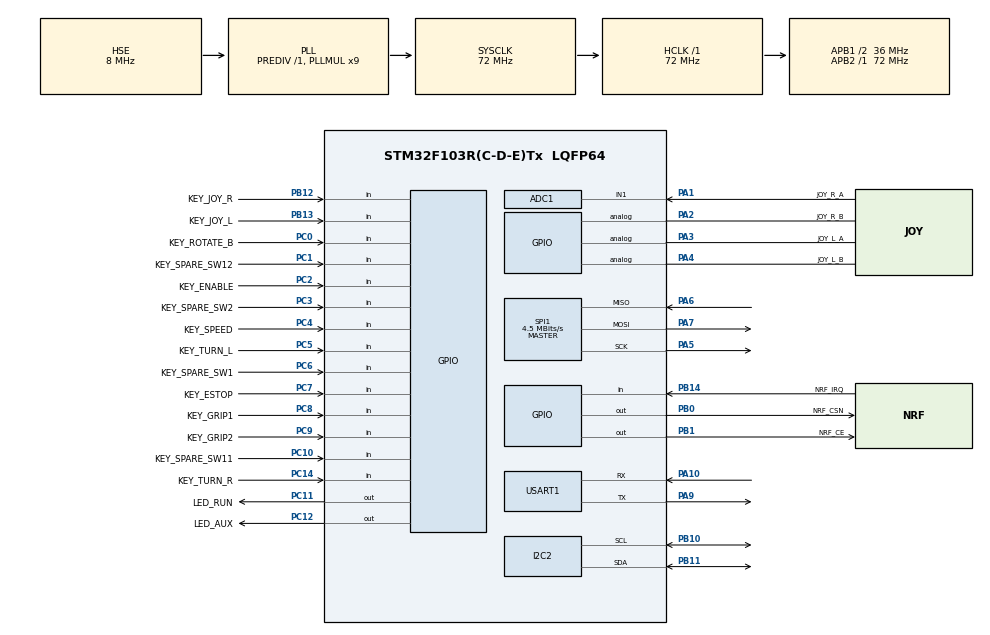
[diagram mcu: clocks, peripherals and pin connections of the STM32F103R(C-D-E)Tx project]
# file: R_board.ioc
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ADC1.Channel-0\#ChannelRegularConversion=ADC_CHANNEL_1
ADC1.NbrOfConversionFlag=1
ADC1.Rank-0\#ChannelRegularConversion=1
ADC1.SamplingTime-0\#ChannelRegularConversion=ADC_SAMPLETIME_239CYCLES_5
ADC1.master=1
I2C2.NoStretchMode=I2C_NOSTRETCH_ENABLE
Mcu.Family=STM32F1
Mcu.Name=STM32F103R(C-D-E)Tx
Mcu.Package=LQFP64
NVIC.PriorityGroup=NVIC_PRIORITYGROUP_4
PA1.GPIO_Label=JOY_R_A
PA1.Signal=ADCx_IN1
PA10.Mode=Asynchronous
PA10.Signal=USART1_RX
PA13.Mode=Serial_Wire
PA13.Signal=SYS_JTMS-SWDIO
PA14.Mode=Serial_Wire
PA14.Signal=SYS_JTCK-SWCLK
PA2.GPIO_Label=JOY_R_B
PA2.Signal=GPIO_Analog
PA3.GPIO_Label=JOY_L_A
PA3.Signal=GPIO_Analog
PA4.GPIO_Label=JOY_L_B
PA4.Signal=GPIO_Analog
PA5.Mode=Full_Duplex_Master
PA5.Signal=SPI1_SCK
PA6.Mode=Full_Duplex_Master
PA6.Signal=SPI1_MISO
PA7.Mode=Full_Duplex_Master
PA7.Signal=SPI1_MOSI
PA9.Mode=Asynchronous
PA9.Signal=USART1_TX
PB0.GPIO_Label=NRF_CSN
PB0.GPIO_PuPd=GPIO_NOPULL
PB0.PinState=GPIO_PIN_SET
PB0.Signal=GPIO_Output
PB1.GPIO_Label=NRF_CE
PB1.Signal=GPIO_Output
PB10.Mode=I2C
PB10.Signal=I2C2_SCL
PB11.Mode=I2C
PB11.Signal=I2C2_SDA
PB12.GPIO_Label=KEY_JOY_R
PB12.GPIO_PuPd=GPIO_PULLUP
PB12.Signal=GPIO_Input
PB13.GPIO_Label=KEY_JOY_L
PB13.GPIO_PuPd=GPIO_PULLUP
PB13.Signal=GPIO_Input
PB14.GPIO_Label=NRF_IRQ
PB14.Signal=GPIO_Input
PC0.GPIO_Label=KEY_ROTATE_B
PC0.GPIO_PuPd=GPIO_PULLUP
PC0.Signal=GPIO_Input
PC1.GPIO_Label=KEY_SPARE_SW12
PC1.GPIO_PuPd=GPIO_PULLUP
PC1.Signal=GPIO_Input
PC10.GPIO_Label=KEY_SPARE_SW11
PC10.GPIO_PuPd=GPIO_PULLUP
PC10.Signal=GPIO_Input
PC11.GPIO_Label=LED_RUN
PC11.GPIO_Speed=GPIO_SPEED_FREQ_HIGH
PC11.Signal=GPIO_Output
PC12.GPIO_Label=LED_AUX
PC12.PinState=GPIO_PIN_SET
PC12.Signal=GPIO_Output
PC14-OSC32_IN.GPIO_Label=KEY_TURN_R
PC14-OSC32_IN.GPIO_PuPd=GPIO_PULLUP
PC14-OSC32_IN.Signal=GPIO_Input
PC2.GPIO_Label=KEY_ENABLE
PC2.GPIO_PuPd=GPIO_PULLUP
PC2.Signal=GPIO_Input
PC3.GPIO_Label=KEY_SPARE_SW2
PC3.GPIO_PuPd=GPIO_PULLUP
PC3.Signal=GPIO_Input
PC4.GPIO_Label=KEY_SPEED
PC4.GPIO_PuPd=GPIO_PULLUP
PC4.Signal=GPIO_Input
PC5.GPIO_Label=KEY_TURN_L
PC5.GPIO_PuPd=GPIO_PULLUP
PC5.Signal=GPIO_Input
PC6.GPIO_Label=KEY_SPARE_SW1
PC6.GPIO_PuPd=GPIO_PULLUP
PC6.Signal=GPIO_Input
PC7.GPIO_Label=KEY_ESTOP
PC7.GPIO_PuPd=GPIO_PULLUP
PC7.Signal=GPIO_Input
PC8.GPIO_Label=KEY_GRIP1
PC8.GPIO_PuPd=GPIO_PULLUP
PC8.Signal=GPIO_Input
PC9.GPIO_Label=KEY_GRIP2
PC9.GPIO_PuPd=GPIO_PULLUP
PC9.Signal=GPIO_Input
PD0-OSC_IN.Mode=HSE-External-Oscillator
PD0-OSC_IN.Signal=RCC_OSC_IN
PD1-OSC_OUT.Mode=HSE-External-Oscillator
PD1-OSC_OUT.Signal=RCC_OSC_OUT
ProjectManager.HeapSize=0x200
ProjectManager.StackSize=0x400
ProjectManager.TargetToolchain=CMake
RCC.ADCPresc=RCC_ADCPCLK2_DIV6
RCC.AHBFreq_Value=72000000
RCC.APB1CLKDivider=RCC_HCLK_DIV2
RCC.APB1Freq_Value=36000000
RCC.APB1TimFreq_Value=72000000
RCC.APB2Freq_Value=72000000
RCC.APB2TimFreq_Value=72000000
RCC.HCLKFreq_Value=72000000
RCC.PLLMUL=RCC_PLL_MUL9
RCC.PLLSourceVirtual=RCC_PLLSOURCE_HSE
RCC.SYSCLKFreq_VALUE=72000000
RCC.SYSCLKSource=RCC_SYSCLKSOURCE_PLLCLK
RCC.USBFreq_Value=72000000
SH.ADCx_IN1.0=ADC1_IN1,IN1
SPI1.BaudRatePrescaler=SPI_BAUDRATEPRESCALER_16
SPI1.CalculateBaudRate=4.5 MBits/s
SPI1.Direction=SPI_DIRECTION_2LINES
SPI1.Mode=SPI_MODE_MASTER
SPI1.VirtualType=VM_MASTER
TIM2.Prescaler=72-1
USART1.VirtualMode=VM_ASYNC
VP_TIM2_VS_ClockSourceINT.Mode=Internal
board=custom

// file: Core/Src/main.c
/* USER CODE BEGIN Header */
/**
  ******************************************************************************
  * @file           : main.c
  * @brief          : Main program body
  ******************************************************************************
  * @attention
  *
  * Copyright (c) 2026 STMicroelectronics.
  * All rights reserved.
  *
  * This software is licensed under terms that can be found in the LICENSE file
  * in the root directory of this software component.
  * If no LICENSE file comes with this software, it is provided AS-IS.
  *
  ******************************************************************************
  */
/* USER CODE END Header */
#include "main.h"
#include "adc.h"
#include "i2c.h"
#include "spi.h"
#include "tim.h"
#include "usart.h"
#include "gpio.h"

/* USER CODE BEGIN Includes */
#include "rboard_app.h"
/* USER CODE END Includes */

void SystemClock_Config(void);

int main(void)
{

  /* MCU Configuration--------------------------------------------------------*/

  /* Reset of all peripherals, Initializes the Flash interface and the Systick. */
  HAL_Init();

  /* Configure the system clock */
  SystemClock_Config();

  /* Initialize all configured peripherals */
  MX_GPIO_Init();
  MX_ADC1_Init();
  MX_I2C2_Init();
  MX_SPI1_Init();
  MX_TIM2_Init();
  MX_USART1_UART_Init();
  /* USER CODE BEGIN 2 */
  RBoardApp_Init();
  /* USER CODE END 2 */

  /* Infinite loop */
  while (1)
  {

    /* USER CODE BEGIN 3 */
    RBoardApp_Process();
    HAL_Delay(1);
  }
  /* USER CODE END 3 */
}

void SystemClock_Config(void)
{
  RCC_OscInitTypeDef RCC_OscInitStruct = {0};
  RCC_ClkInitTypeDef RCC_ClkInitStruct = {0};
  RCC_PeriphCLKInitTypeDef PeriphClkInit = {0};

  /** Initializes the RCC Oscillators according to the specified parameters
  * in the RCC_OscInitTypeDef structure.
  */
  RCC_OscInitStruct.OscillatorType = RCC_OSCILLATORTYPE_HSE;
  RCC_OscInitStruct.HSEState = RCC_HSE_ON;
  RCC_OscInitStruct.HSEPredivValue = RCC_HSE_PREDIV_DIV1;
  RCC_OscInitStruct.HSIState = RCC_HSI_ON;
  RCC_OscInitStruct.PLL.PLLState = RCC_PLL_ON;
  RCC_OscInitStruct.PLL.PLLSource = RCC_PLLSOURCE_HSE;
  RCC_OscInitStruct.PLL.PLLMUL = RCC_PLL_MUL9;
  if (HAL_RCC_OscConfig(&RCC_OscInitStruct) != HAL_OK)
  {
    Error_Handler();
  }

  /** Initializes the CPU, AHB and APB buses clocks
  */
  RCC_ClkInitStruct.ClockType = RCC_CLOCKTYPE_HCLK|RCC_CLOCKTYPE_SYSCLK
                              |RCC_CLOCKTYPE_PCLK1|RCC_CLOCKTYPE_PCLK2;
  RCC_ClkInitStruct.SYSCLKSource = RCC_SYSCLKSOURCE_PLLCLK;
  RCC_ClkInitStruct.AHBCLKDivider = RCC_SYSCLK_DIV1;
  RCC_ClkInitStruct.APB1CLKDivider = RCC_HCLK_DIV2;
  RCC_ClkInitStruct.APB2CLKDivider = RCC_HCLK_DIV1;

  if (HAL_RCC_ClockConfig(&RCC_ClkInitStruct, FLASH_LATENCY_2) != HAL_OK)
  {
    Error_Handler();
  }
  PeriphClkInit.PeriphClockSelection = RCC_PERIPHCLK_ADC;
  PeriphClkInit.AdcClockSelection = RCC_ADCPCLK2_DIV6;
  if (HAL_RCCEx_PeriphCLKConfig(&PeriphClkInit) != HAL_OK)
  {
    Error_Handler();
  }
}

void Error_Handler(void)
{
  __disable_irq();
  while (1)
  {
  }
}
